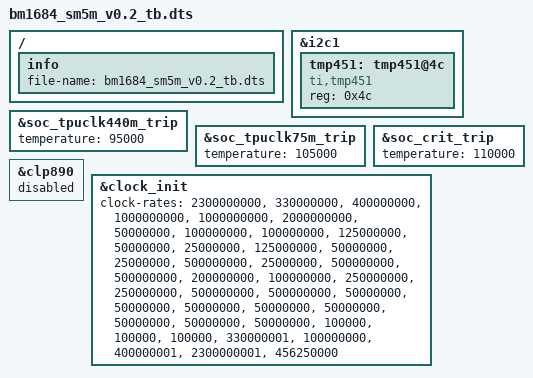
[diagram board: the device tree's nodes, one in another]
#include "bm1684.dtsi"
#include "bm1684_mm_6g.dtsi"
#include "bm1684_sm5_tb.dtsi"

/ {
	info {
		file-name = "bm1684_sm5m_v0.2_tb.dts";
	};
};

&i2c1 {
	/delete-node/ tmp451@6b;

	tmp451: tmp451@4c {
		compatible = "ti,tmp451";
		reg = <0x4c>;
		#thermal-sensor-cells = <1>;
	};
};

&soc_tpuclk440m_trip {
	temperature = <95000>;
};

&soc_tpuclk75m_trip {
	temperature = <105000>;
};

&soc_crit_trip {
	temperature = <110000>;
};

&clp890 {
	status = "disabled";
};

&clock_init {
	clock-rates = \
		<2300000000>, <330000000>, <400000000>,

		<1000000000>, <1000000000>,
		<2000000000>, <50000000>,
		<100000000>, <100000000>,
		<125000000>, <50000000>,
		<25000000>, <125000000>,
		<50000000>, <25000000>,
		<500000000>, <25000000>,
		<500000000>, <500000000>,
		<200000000>, <100000000>,
		<250000000>, <250000000>,
		<500000000>, <500000000>,
		<50000000>, <50000000>,
		<50000000>, <50000000>,
		<50000000>, <50000000>,
		<50000000>, <50000000>,
		<100000>, <100000>, <100000>,

		<330000001>,
		<100000000>, <400000001>,
		<2300000001>, <456250000>;
};
